# VPAC0_COMMON_0_IVPAC_TOP_0_CFG_SLV_PAR_VPAC_VISS0_S_VBUSP_VISS_FCP_FCC_VBUSP_FLEXCC register map
Vendor: Texas Instruments
Peripheral module from a debugger description file (folder am62A).
Registers are 32-bit, read-write, reset 0x0 unless marked. A register's access mark holds for its fields unless they carry their own. Offsets are as the file gives them; lines under a group give offsets from that group; [hi:lo] are bit positions; {n}, {i} and the like mark numbered series; 'fields as' and 'values as' point back to an identical list; <NAME> marks a mode.

## VPAC0_COMMON_0_IVPAC_TOP_0_CFG_SLV_PAR_VPAC_VISS0_S_VBUSP_VISS_FCP_FCC_VBUSP_FLEXCC
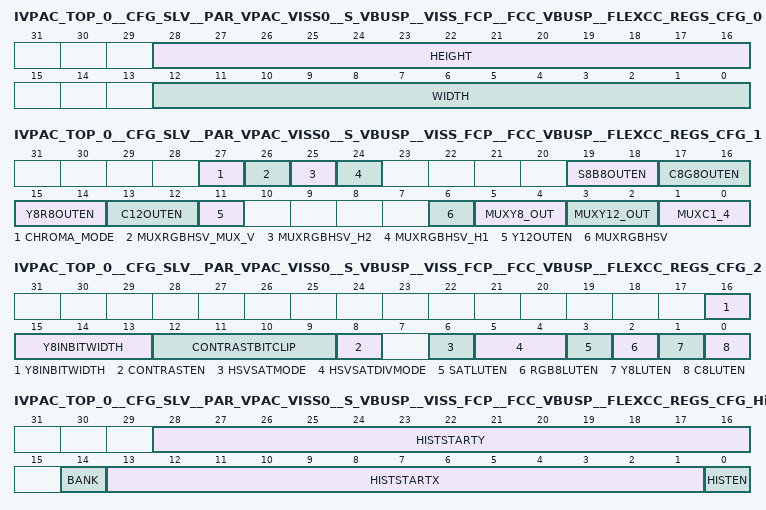
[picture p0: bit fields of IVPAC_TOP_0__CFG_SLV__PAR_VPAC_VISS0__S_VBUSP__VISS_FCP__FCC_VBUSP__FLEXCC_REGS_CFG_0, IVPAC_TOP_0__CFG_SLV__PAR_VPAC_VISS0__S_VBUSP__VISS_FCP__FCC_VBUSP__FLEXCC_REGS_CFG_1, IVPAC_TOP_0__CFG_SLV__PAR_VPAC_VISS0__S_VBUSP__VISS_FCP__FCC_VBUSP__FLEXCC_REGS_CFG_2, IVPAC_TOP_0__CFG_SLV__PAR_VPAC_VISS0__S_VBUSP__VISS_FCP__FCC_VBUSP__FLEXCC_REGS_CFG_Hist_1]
0x00 IVPAC_TOP_0__CFG_SLV__PAR_VPAC_VISS0__S_VBUSP__VISS_FCP__FCC_VBUSP__FLEXCC_REGS_CFG_0 — The Control Register controls the input width and height of the module.
  [28:16] HEIGHT — Height of the input image
  [12:0] WIDTH — Width of the input image
0x04 IVPAC_TOP_0__CFG_SLV__PAR_VPAC_VISS0__S_VBUSP__VISS_FCP__FCC_VBUSP__FLEXCC_REGS_CFG_1 — Configuration Register for top level data flow
  [27] CHROMA_MODE — Mux for 422/420 (0:420 Chroma ,1: 422 Chroma)
  [26] MUXRGBHSV_MUX_V — Mux for V calculation (0:Select non WB corrected data ,1: Select WB corrected data)
  [25] MUXRGBHSV_H2 — Mux for S/V calculation (0:Select B,1: Select Max(RGB))
  [24] MUXRGBHSV_H1 — Mux for S/V calculation (0:Select R,1: Select Min(RGB))
  [19:18] S8B8OUTEN — '0': Disable All , '1': S8 enable, 2:B8 enable, 3:C4 enable
  [17:16] C8G8OUTEN — '0': Disable All , '1': C8 enable, 2:G8 enable, 3:C3 enable
  [15:14] Y8R8OUTEN — '0': Disable all , '1': Y8 enable, 2:R8 enable, 3:C2 enable
  [13:12] C12OUTEN — '0': Disable all , '1': C12 enable, '2': C1 enable
  [11] Y12OUTEN — '0': Disable Y12 output, '1': Enable Y12 output
  [6] MUXRGBHSV — Input Select for RGBHSV (0:In after Contrast,1: In before Contrast)
  [5:4] MUXY8_OUT — Mux for Y-8 Output (0:MuxC1_4, 1:RGB2YUV, 2:RGB2HSV)
  [3:2] MUXY12_OUT — Mux for Y-12 Output (0:MuxC1_4, 1:RGB2YUV, 2:RGB2HSV, 3:C1 enable)
  [1:0] MUXC1_4 — Mux for selecting C input (0:C0, 1:C1, 2:C2, 3:C3)
0x08 IVPAC_TOP_0__CFG_SLV__PAR_VPAC_VISS0__S_VBUSP__VISS_FCP__FCC_VBUSP__FLEXCC_REGS_CFG_2 — Configuration Register-2
  [16:13] Y8INBITWIDTH — Bitwidth of input to 12to8 module (Y8) for shift(Program as 12 or lower)
  [12:9] CONTRASTBITCLIP — Clip Value set as 2^ContrastBitClip -1
  [8] CONTRASTEN — 0:Disable, 1: Enable Contrast
  [6] HSVSATMODE — 0:Max(RGB) - Min(RGB), 1:Sum(RGB) - Min(RGB)
  [5:4] HSVSATDIVMODE — 0:One, 1:Max(RGB), 2: 4095 -V, 3:Sum(RGB)
  [3] SATLUTEN — '1':Use LUT, '0':Use shift
  [2] RGB8LUTEN — '1':Use LUT, '0':Use shift
  [1] Y8LUTEN — '1':Use LUT, '0':Use shift
  [0] C8LUTEN — '1':Use LUT, '0':Use shift
0x0C IVPAC_TOP_0__CFG_SLV__PAR_VPAC_VISS0__S_VBUSP__VISS_FCP__FCC_VBUSP__FLEXCC_REGS_CFG_Hist_1 — Configuration-1 Register for histogram
  [28:16] HISTSTARTY — Y Start for Histogram ROI, should be >= 1
  [14] BANK — bank select for Histogram
  [13:1] HISTSTARTX — X Start for Histogram ROI, should be even
  [0] HISTEN — Enable bit for histogram
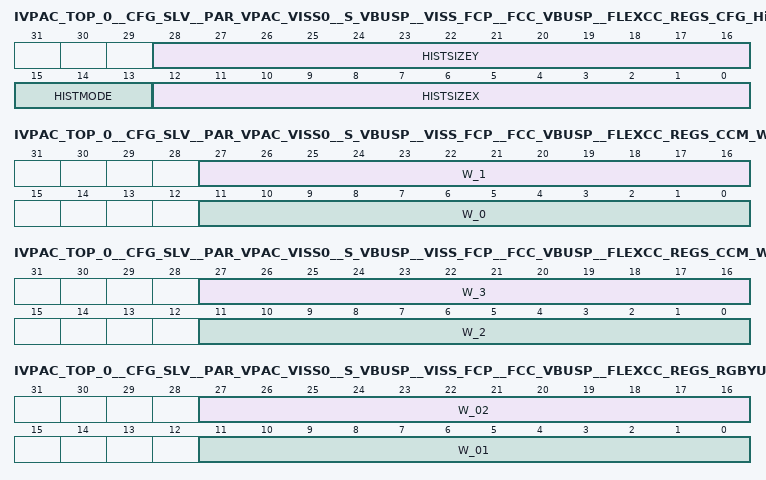
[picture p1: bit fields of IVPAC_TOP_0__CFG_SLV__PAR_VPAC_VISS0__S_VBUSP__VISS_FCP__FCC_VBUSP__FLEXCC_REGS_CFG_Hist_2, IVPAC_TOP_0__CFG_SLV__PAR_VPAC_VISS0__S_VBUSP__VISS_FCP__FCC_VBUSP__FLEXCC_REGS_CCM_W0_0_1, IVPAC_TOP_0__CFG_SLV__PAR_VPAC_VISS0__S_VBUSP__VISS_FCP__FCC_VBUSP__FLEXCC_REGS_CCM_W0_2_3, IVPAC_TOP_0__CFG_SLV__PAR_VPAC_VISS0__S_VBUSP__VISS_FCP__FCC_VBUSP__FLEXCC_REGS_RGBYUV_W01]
0x10 IVPAC_TOP_0__CFG_SLV__PAR_VPAC_VISS0__S_VBUSP__VISS_FCP__FCC_VBUSP__FLEXCC_REGS_CFG_Hist_2 — Configuration-2 Register for histogram
  [28:16] HISTSIZEY — Y Size (Height) for Histogram ROI
  [15:13] HISTMODE — Histogram Mode 0:Col-0(R), 1:Col-1(G), 2:Col-2(B), 3:MuxC1_4, 4:(R+2G+B)/4, 5:Col-0(R)
  [12:0] HISTSIZEX — X Size (Width) for Histogram ROI, should be > 256 & even
{0x14+0xC*i} IVPAC_TOP_0__CFG_SLV__PAR_VPAC_VISS0__S_VBUSP__VISS_FCP__FCC_VBUSP__FLEXCC_REGS_CCM_W{i}_0_1 (i=0..2) — CCM Weights for Row{i}
  [27:16] W_1 — Weight W_{10i+1:02} : (S12 b)
  [11:0] W_0 — Weight W_{10i:02} : (S12 b)
{0x18+0xC*i} IVPAC_TOP_0__CFG_SLV__PAR_VPAC_VISS0__S_VBUSP__VISS_FCP__FCC_VBUSP__FLEXCC_REGS_CCM_W{i}_2_3 (i=0..2) — CCM Weights for Row{i}
  [27:16] W_3 — Weight W_{10i+3:02} : (S12 b)
  [11:0] W_2 — Weight W_{10i+2:02} : (S12 b)
{0x1C+0xC*i} IVPAC_TOP_0__CFG_SLV__PAR_VPAC_VISS0__S_VBUSP__VISS_FCP__FCC_VBUSP__FLEXCC_REGS_CCM_OFFSET_{i} (i=0..2) — CCM OFFSET for Row{i}
  [12:0] OFFSET_{i} — OFFSET_{i} : (S13 b)
0x38 IVPAC_TOP_0__CFG_SLV__PAR_VPAC_VISS0__S_VBUSP__VISS_FCP__FCC_VBUSP__FLEXCC_REGS_RGBYUV_W01 — Weight/Offset for Row0
  [27:16] W_02 — Weight W_02 : (S12 b)
  [11:0] W_01 — Weight W_01 : (S12 b)
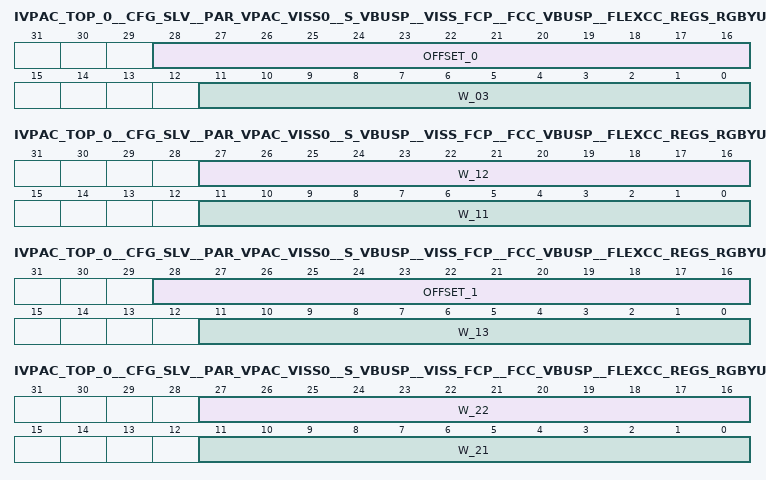
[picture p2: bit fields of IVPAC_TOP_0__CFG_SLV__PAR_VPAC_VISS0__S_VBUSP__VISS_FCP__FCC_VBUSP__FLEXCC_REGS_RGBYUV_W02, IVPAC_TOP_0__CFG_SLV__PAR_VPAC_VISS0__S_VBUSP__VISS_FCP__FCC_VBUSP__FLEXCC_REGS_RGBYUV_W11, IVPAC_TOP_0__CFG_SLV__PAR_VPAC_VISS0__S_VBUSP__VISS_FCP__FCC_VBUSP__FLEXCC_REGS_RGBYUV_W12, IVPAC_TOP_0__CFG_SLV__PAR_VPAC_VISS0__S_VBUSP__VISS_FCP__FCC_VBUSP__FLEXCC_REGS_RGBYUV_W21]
0x3C IVPAC_TOP_0__CFG_SLV__PAR_VPAC_VISS0__S_VBUSP__VISS_FCP__FCC_VBUSP__FLEXCC_REGS_RGBYUV_W02 — Weight/Offset for Row0
  [28:16] OFFSET_0 — Offset_0 : (S13b)
  [11:0] W_03 — Weight W_03 : (S12 b)
0x40 IVPAC_TOP_0__CFG_SLV__PAR_VPAC_VISS0__S_VBUSP__VISS_FCP__FCC_VBUSP__FLEXCC_REGS_RGBYUV_W11 — Weight/Offset for Row1
  [27:16] W_12 — Weight W_12 : (S12 b)
  [11:0] W_11 — Weight W_11 : (S12 b)
0x44 IVPAC_TOP_0__CFG_SLV__PAR_VPAC_VISS0__S_VBUSP__VISS_FCP__FCC_VBUSP__FLEXCC_REGS_RGBYUV_W12 — Weight/Offset for Row1
  [28:16] OFFSET_1 — Offset_1 : (S13b)
  [11:0] W_13 — Weight W_13 : (S12 b)
0x48 IVPAC_TOP_0__CFG_SLV__PAR_VPAC_VISS0__S_VBUSP__VISS_FCP__FCC_VBUSP__FLEXCC_REGS_RGBYUV_W21 — Weight/Offset for Row2
  [27:16] W_22 — Weight W_22 : (S12 b)
  [11:0] W_21 — Weight W_21 : (S12 b)
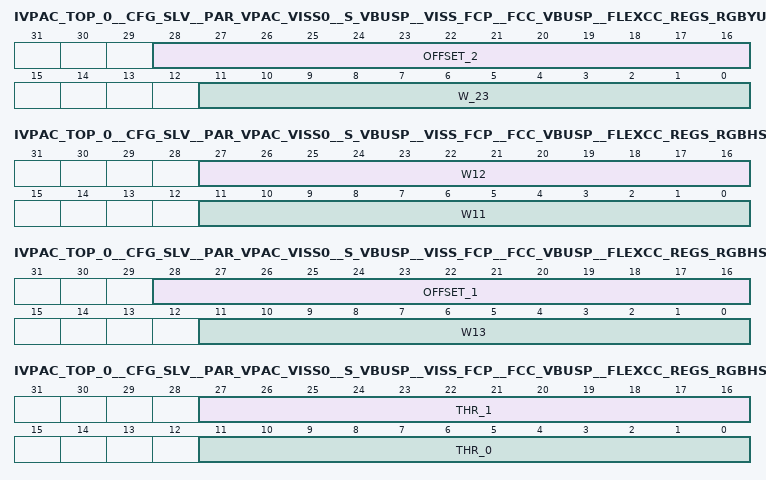
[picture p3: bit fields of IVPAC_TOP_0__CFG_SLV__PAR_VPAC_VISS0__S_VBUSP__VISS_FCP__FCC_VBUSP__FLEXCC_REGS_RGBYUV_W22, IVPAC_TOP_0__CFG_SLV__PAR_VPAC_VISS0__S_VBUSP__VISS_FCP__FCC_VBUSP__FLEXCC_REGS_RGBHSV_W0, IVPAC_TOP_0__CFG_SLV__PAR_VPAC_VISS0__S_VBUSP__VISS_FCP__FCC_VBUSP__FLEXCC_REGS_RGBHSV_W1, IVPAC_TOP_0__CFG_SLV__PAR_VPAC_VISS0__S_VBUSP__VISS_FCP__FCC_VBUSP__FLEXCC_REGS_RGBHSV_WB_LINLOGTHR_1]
0x4C IVPAC_TOP_0__CFG_SLV__PAR_VPAC_VISS0__S_VBUSP__VISS_FCP__FCC_VBUSP__FLEXCC_REGS_RGBYUV_W22 — Weight/Offset for Row2
  [28:16] OFFSET_2 — Offset_2 : (S13b)
  [11:0] W_23 — Weight W_23 : (S12 b)
0x50 IVPAC_TOP_0__CFG_SLV__PAR_VPAC_VISS0__S_VBUSP__VISS_FCP__FCC_VBUSP__FLEXCC_REGS_RGBHSV_W0 — Weights 11/12 for V calculation
  [27:16] W12 — Weight W12 (Signed 12b)
  [11:0] W11 — Weight W11 (Signed 12b)
0x54 IVPAC_TOP_0__CFG_SLV__PAR_VPAC_VISS0__S_VBUSP__VISS_FCP__FCC_VBUSP__FLEXCC_REGS_RGBHSV_W1 — Weights13 and Offset_1 for V Calculation
  [28:16] OFFSET_1 — Offset_1 (Signed 13b)
  [11:0] W13 — Weight W13 (Signed 12b)
0x58 IVPAC_TOP_0__CFG_SLV__PAR_VPAC_VISS0__S_VBUSP__VISS_FCP__FCC_VBUSP__FLEXCC_REGS_RGBHSV_WB_LINLOGTHR_1 — Dynamic WB Thr limit
  [27:16] THR_1 — THR_1 / G-Channel Thr (U 12b)
  [11:0] THR_0 — THR_0 / R-Channel Thr (U 12b)
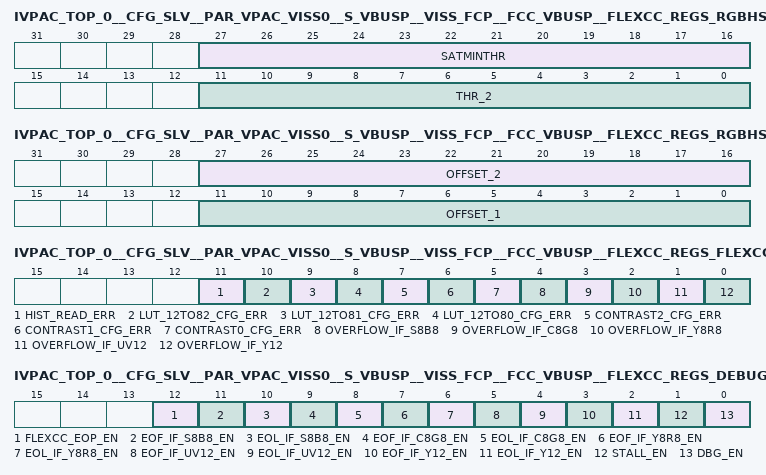
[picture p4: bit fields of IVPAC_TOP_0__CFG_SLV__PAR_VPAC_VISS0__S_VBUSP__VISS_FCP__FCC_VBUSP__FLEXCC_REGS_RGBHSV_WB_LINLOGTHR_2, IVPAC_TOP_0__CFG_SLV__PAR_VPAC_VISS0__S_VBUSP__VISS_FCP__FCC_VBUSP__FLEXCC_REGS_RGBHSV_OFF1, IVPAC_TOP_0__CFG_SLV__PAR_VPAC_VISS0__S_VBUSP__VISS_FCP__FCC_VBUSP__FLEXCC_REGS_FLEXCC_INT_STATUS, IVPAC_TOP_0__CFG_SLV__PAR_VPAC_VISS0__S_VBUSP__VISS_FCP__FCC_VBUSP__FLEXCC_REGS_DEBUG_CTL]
0x5C IVPAC_TOP_0__CFG_SLV__PAR_VPAC_VISS0__S_VBUSP__VISS_FCP__FCC_VBUSP__FLEXCC_REGS_RGBHSV_WB_LINLOGTHR_2 — Dynamic WB Thr limit and SatMinThr
  [27:16] SATMINTHR — Thr for comparing Min(RGB) limit
  [11:0] THR_2 — THR_2 / B-Channel Thr (U 12b)
0x60 IVPAC_TOP_0__CFG_SLV__PAR_VPAC_VISS0__S_VBUSP__VISS_FCP__FCC_VBUSP__FLEXCC_REGS_RGBHSV_OFF1 — WB Offset for Saturation
  [27:16] OFFSET_2 — Offset_2 (U 12b)
  [11:0] OFFSET_1 — Offset-1 (U 12b)
0x64 IVPAC_TOP_0__CFG_SLV__PAR_VPAC_VISS0__S_VBUSP__VISS_FCP__FCC_VBUSP__FLEXCC_REGS_RGBHSV_OFF2 — WB Offsets for Saturation
  [11:0] OFFSET_3 — Offset-3 (U 12b)
0x68 IVPAC_TOP_0__CFG_SLV__PAR_VPAC_VISS0__S_VBUSP__VISS_FCP__FCC_VBUSP__FLEXCC_REGS_FLEXCC_INT_STATUS access not given — Status/clear register for flexcc interrupts
  [11] HIST_READ_ERR — status/clear for histogram memory, set when mem access has occurred to the first location but not to the last location during active frame implying that full histogram was not read . Write 1 to clear, write 0 has no effect (access R/W1TC)
  [10] LUT_12TO82_CFG_ERR — status/clear for 12to8_2_lut cfg err, set when mem access occurs during active line when the LUT is enabled causing frame corruption. Write 1 to clear, write 0 has no effect (access R/W1TC)
  [9] LUT_12TO81_CFG_ERR — status/clear for 12to8_1_lut cfg err, set when mem access occurs during active line when the LUT is enabled causing frame corruption. Write 1 to clear, write 0 has no effect (access R/W1TC)
  [8] LUT_12TO80_CFG_ERR — status/clear for 12to8_0_lut cfg err, set when mem access occurs during active line when the LUT is enabled causing frame corruption. Write 1 to clear, write 0 has no effect (access R/W1TC)
  [7] CONTRAST2_CFG_ERR — status/clear for contrast2_lut cfg err, set when mem access occurs during active line when the LUT is enabled causing frame corruption. Write 1 to clear, write 0 has no effect (access R/W1TC)
  [6] CONTRAST1_CFG_ERR — status/clear for contrast1_lut cfg err, set when mem access occurs during active line when the LUT is enabled causing frame corruption. Write 1 to clear, write 0 has no effect (access R/W1TC)
  [5] CONTRAST0_CFG_ERR — status/clear for contrast0_lut cfg err, set when mem access occurs during active line when the LUT is enabled causing frame corruption. Write 1 to clear, write 0 has no effect (access R/W1TC)
  [4] OVERFLOW_IF_S8B8 — status/clear for overflow on s8b8 i/f, set when fifo overflows causing frame corruption. Write 1 to clear, write 0 has no effect (access R/W1TC)
  [3] OVERFLOW_IF_C8G8 — status/clear for overflow on c8g8 i/f, set when fifo overflows causing frame corruption. Write 1 to clear, write 0 has no effect (access R/W1TC)
  [2] OVERFLOW_IF_Y8R8 — status/clear for overflow on y8r8 i/f, set when fifo overflows causing frame corruption. Write 1 to clear, write 0 has no effect (access R/W1TC)
  [1] OVERFLOW_IF_UV12 — status/clear for overflow on uv12 i/f, set when fifo overflows causing frame corruption. Write 1 to clear, write 0 has no effect (access R/W1TC)
  [0] OVERFLOW_IF_Y12 — status/clear for overflow on y12 i/f, set when fifo overflows causing frame corruption. Write 1 to clear, write 0 has no effect (access R/W1TC)
0x100 IVPAC_TOP_0__CFG_SLV__PAR_VPAC_VISS0__S_VBUSP__VISS_FCP__FCC_VBUSP__FLEXCC_REGS_DEBUG_CTL — Enable for different debug events
  [12] FLEXCC_EOP_EN — Enable for flexcc eop
  [11] EOF_IF_S8B8_EN — Enable for eof on s8b8
  [10] EOL_IF_S8B8_EN — Enable for eol on s8b8
  [9] EOF_IF_C8G8_EN — Enable for eof on c8g8
  [8] EOL_IF_C8G8_EN — Enable for eol on c8g8
  [7] EOF_IF_Y8R8_EN — Enable for eof on y8r8
  [6] EOL_IF_Y8R8_EN — Enable for eol on y8r8
  [5] EOF_IF_UV12_EN — Enable for eof on uv12
  [4] EOL_IF_UV12_EN — Enable for eol on uv12
  [3] EOF_IF_Y12_EN — Enable for eof on y12
  [2] EOL_IF_Y12_EN — Enable for eol on y12
  [1] STALL_EN — Enable for stall event
  [0] DBG_EN — Enable debug features, set to '0' to disable all debug events
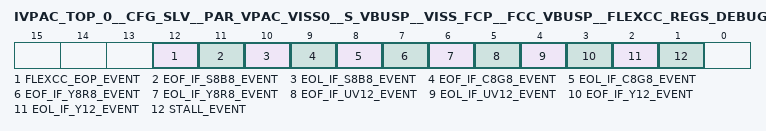
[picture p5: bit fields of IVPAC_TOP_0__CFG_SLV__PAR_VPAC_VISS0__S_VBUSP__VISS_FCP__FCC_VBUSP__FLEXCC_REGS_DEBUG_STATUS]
0x104 IVPAC_TOP_0__CFG_SLV__PAR_VPAC_VISS0__S_VBUSP__VISS_FCP__FCC_VBUSP__FLEXCC_REGS_DEBUG_STATUS access not given — Set/Clear for debug events
  [12] FLEXCC_EOP_EVENT — Status/Clear for flexcc eop, write '1' to clear (access R/W1TC)
  [11] EOF_IF_S8B8_EVENT — Status/Clear for eof on s8b8, write '1' to clear (access R/W1TC)
  [10] EOL_IF_S8B8_EVENT — Status/Clear for eol on s8b8, write '1' to clear (access R/W1TC)
  [9] EOF_IF_C8G8_EVENT — Status/Clear for eof on c8g8, write '1' to clear (access R/W1TC)
  [8] EOL_IF_C8G8_EVENT — Status/Clear for eol on c8g8, write '1' to clear (access R/W1TC)
  [7] EOF_IF_Y8R8_EVENT — Status/Clear for eof on y8r8, write '1' to clear (access R/W1TC)
  [6] EOL_IF_Y8R8_EVENT — Status/Clear for eol on y8r8, write '1' to clear (access R/W1TC)
  [5] EOF_IF_UV12_EVENT — Status/Clear for eof on uv12, write '1' to clear (access R/W1TC)
  [4] EOL_IF_UV12_EVENT — Status/Clear for eol on uv12, write '1' to clear (access R/W1TC)
  [3] EOF_IF_Y12_EVENT — Status/Clear for eof on y12, write '1' to clear (access R/W1TC)
  [2] EOL_IF_Y12_EVENT — Status/Clear for eol on y12, write '1' to clear (access R/W1TC)
  [1] STALL_EVENT — Status/Clear for stall event, write '1' to clear (access R/W1TC)
0x108 IVPAC_TOP_0__CFG_SLV__PAR_VPAC_VISS0__S_VBUSP__VISS_FCP__FCC_VBUSP__FLEXCC_REGS_DEBUG_RAW — Set/Clear for debug RAW mode
  [0] DBG_RAW_MODE — Enable debug RAW mode, takes input from RAWFE and delivers to FlexCC as C1={raw[11:0]}, C2={4'd0,raw[7:0]}, C3={4'd0,raw[15:8]}, c4={8'd0,raw[15:12]}
